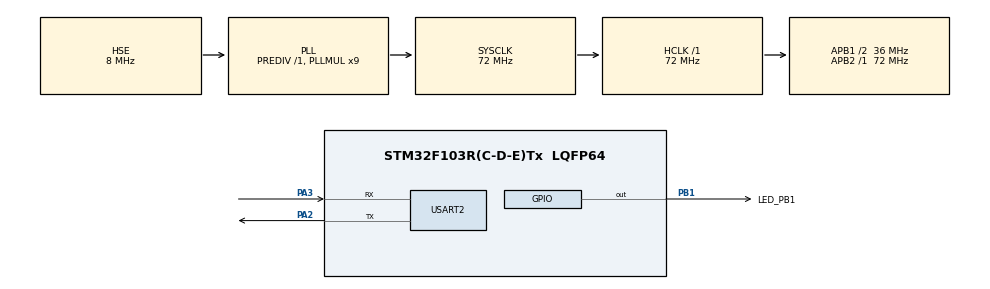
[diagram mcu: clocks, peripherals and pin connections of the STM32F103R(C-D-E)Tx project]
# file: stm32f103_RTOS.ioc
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FREERTOS.Tasks01=defaultTask,0,128,StartDefaultTask,Default,NULL
Mcu.Family=STM32F1
Mcu.Name=STM32F103R(C-D-E)Tx
Mcu.Package=LQFP64
NVIC.PriorityGroup=NVIC_PRIORITYGROUP_4
NVIC.TIM7_IRQn=true\:0\:0\:false\:false\:true\:false\:false\:true
NVIC.TimeBase=TIM7_IRQn
NVIC.TimeBaseIP=TIM7
NVIC.USART2_IRQn=true\:5\:0\:false\:false\:true\:true\:true\:true
PA13.Mode=Trace_Asynchronous_SW
PA13.Signal=SYS_JTMS-SWDIO
PA14.Mode=Trace_Asynchronous_SW
PA14.Signal=SYS_JTCK-SWCLK
PA2.Mode=Asynchronous
PA2.Signal=USART2_TX
PA3.Mode=Asynchronous
PA3.Signal=USART2_RX
PB1.GPIO_Label=LED_PB1
PB1.PinState=GPIO_PIN_SET
PB1.Signal=GPIO_Output
PB3.Mode=Trace_Asynchronous_SW
PB3.Signal=SYS_JTDO-TRACESWO
PD0-OSC_IN.Mode=HSE-External-Oscillator
PD0-OSC_IN.Signal=RCC_OSC_IN
PD1-OSC_OUT.Mode=HSE-External-Oscillator
PD1-OSC_OUT.Signal=RCC_OSC_OUT
ProjectManager.HeapSize=0x200
ProjectManager.StackSize=0x400
ProjectManager.TargetToolchain=TrueSTUDIO
RCC.AHBFreq_Value=72000000
RCC.APB1CLKDivider=RCC_HCLK_DIV2
RCC.APB1Freq_Value=36000000
RCC.APB1TimFreq_Value=72000000
RCC.APB2Freq_Value=72000000
RCC.APB2TimFreq_Value=72000000
RCC.HCLKFreq_Value=72000000
RCC.PLLMUL=RCC_PLL_MUL9
RCC.PLLSourceVirtual=RCC_PLLSOURCE_HSE
RCC.SYSCLKFreq_VALUE=72000000
RCC.SYSCLKSource=RCC_SYSCLKSOURCE_PLLCLK
RCC.USBFreq_Value=72000000
USART2.VirtualMode=VM_ASYNC
VP_FREERTOS_VS_CMSIS_V1.Mode=CMSIS_V1
VP_SYS_VS_tim7.Mode=TIM7
board=custom

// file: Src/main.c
/* USER CODE BEGIN Header */
/**
  ******************************************************************************
  * @file           : main.c
  * @brief          : Main program body
  ******************************************************************************
  * @attention
  *
  * <h2><center>&copy; Copyright (c) 2019 STMicroelectronics.
  * All rights reserved.</center></h2>
  *
  * This software component is licensed by ST under Ultimate Liberty license
  * SLA0044, the "License"; You may not use this file except in compliance with
  * the License. You may obtain a copy of the License at:
  *                             www.st.com/SLA0044
  *
  ******************************************************************************
  */
/* USER CODE END Header */

#include "main.h"
#include "cmsis_os.h"
#include "usart.h"
#include "gpio.h"

/* USER CODE BEGIN PTD */
#ifdef __GNUC__
/* With GCC, small printf (option LD Linker->Libraries->Small printf
   set to 'Yes') calls __io_putchar() */
#define PUTCHAR_PROTOTYPE int __io_putchar(int ch)
#else
#define PUTCHAR_PROTOTYPE int fputc(int ch, FILE *f)
#endif /* __GNUC__ */

/* USER CODE END PTD */

void SystemClock_Config(void);
void MX_FREERTOS_Init(void);

int main(void)
{

  /* MCU Configuration--------------------------------------------------------*/

  /* Reset of all peripherals, Initializes the Flash interface and the Systick. */
  HAL_Init();

  /* Configure the system clock */
  SystemClock_Config();

  /* Initialize all configured peripherals */
  MX_GPIO_Init();
  MX_USART2_UART_Init();

  /* Call init function for freertos objects (in freertos.c) */
  MX_FREERTOS_Init();

  /* Start scheduler */
  osKernelStart();

  /* We should never get here as control is now taken by the scheduler */

  /* Infinite loop */
  /* USER CODE BEGIN WHILE */
  //printf("Test RTOS\r\n");

  while (1)
  {
    /* USER CODE END WHILE */
	  //printf("Test while\r\n");

  }
}

void SystemClock_Config(void)
{
  RCC_OscInitTypeDef RCC_OscInitStruct = {0};
  RCC_ClkInitTypeDef RCC_ClkInitStruct = {0};

  /** Initializes the CPU, AHB and APB busses clocks
  */
  RCC_OscInitStruct.OscillatorType = RCC_OSCILLATORTYPE_HSE;
  RCC_OscInitStruct.HSEState = RCC_HSE_ON;
  RCC_OscInitStruct.HSEPredivValue = RCC_HSE_PREDIV_DIV1;
  RCC_OscInitStruct.HSIState = RCC_HSI_ON;
  RCC_OscInitStruct.PLL.PLLState = RCC_PLL_ON;
  RCC_OscInitStruct.PLL.PLLSource = RCC_PLLSOURCE_HSE;
  RCC_OscInitStruct.PLL.PLLMUL = RCC_PLL_MUL9;
  if (HAL_RCC_OscConfig(&RCC_OscInitStruct) != HAL_OK)
  {
    Error_Handler();
  }
  /** Initializes the CPU, AHB and APB busses clocks
  */
  RCC_ClkInitStruct.ClockType = RCC_CLOCKTYPE_HCLK|RCC_CLOCKTYPE_SYSCLK
                              |RCC_CLOCKTYPE_PCLK1|RCC_CLOCKTYPE_PCLK2;
  RCC_ClkInitStruct.SYSCLKSource = RCC_SYSCLKSOURCE_PLLCLK;
  RCC_ClkInitStruct.AHBCLKDivider = RCC_SYSCLK_DIV1;
  RCC_ClkInitStruct.APB1CLKDivider = RCC_HCLK_DIV2;
  RCC_ClkInitStruct.APB2CLKDivider = RCC_HCLK_DIV1;

  if (HAL_RCC_ClockConfig(&RCC_ClkInitStruct, FLASH_LATENCY_2) != HAL_OK)
  {
    Error_Handler();
  }
}

/* USER CODE BEGIN 4 */

PUTCHAR_PROTOTYPE
{
  /* Place your implementation of fputc here */
  /* e.g. write a character to the USART2 and Loop until the end of transmission */
  HAL_UART_Transmit(&huart2, (uint8_t *)&ch, 1, 0xFFFF);

  return ch;
}

/* USER CODE END 4 */

void HAL_TIM_PeriodElapsedCallback(TIM_HandleTypeDef *htim)
{
  if (htim->Instance == TIM7) {
    HAL_IncTick();
  }
}

void Error_Handler(void)
{
}

/************************ (C) COPYRIGHT STMicroelectronics *****END OF FILE****/

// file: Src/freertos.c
/* USER CODE BEGIN Header */
/**
  ******************************************************************************
  * File Name          : freertos.c
  * Description        : Code for freertos applications
  ******************************************************************************
  * @attention
  *
  * <h2><center>&copy; Copyright (c) 2019 STMicroelectronics.
  * All rights reserved.</center></h2>
  *
  * This software component is licensed by ST under Ultimate Liberty license
  * SLA0044, the "License"; You may not use this file except in compliance with
  * the License. You may obtain a copy of the License at:
  *                             www.st.com/SLA0044
  *
  ******************************************************************************
  */
/* USER CODE END Header */

#include "FreeRTOS.h"
#include "task.h"
#include "main.h"
#include "cmsis_os.h"

osThreadId defaultTaskHandle;

void StartDefaultTask(void const * argument);
void StartDefaultTask1(void const * argument);
void StartDefaultTask2(void const * argument);

void MX_FREERTOS_Init(void); /* (MISRA C 2004 rule 8.1) */

void MX_FREERTOS_Init(void) {

  /* Create the thread(s) */
  /* definition and creation of defaultTask */
  osThreadDef(defaultTask, StartDefaultTask, osPriorityNormal, 0, 128);
  defaultTaskHandle = osThreadCreate(osThread(defaultTask), NULL);

  /* USER CODE BEGIN RTOS_THREADS */
  /* add threads, ... */
  //printf("Start: \r\n");
  osThreadDef(defaultTask2, StartDefaultTask2, osPriorityNormal, 0, 128);
    defaultTaskHandle = osThreadCreate(osThread(defaultTask2), NULL);

    //osThreadDef(defaultTask1, StartDefaultTask1, osPriorityNormal, 0, 128);
        //defaultTaskHandle = osThreadCreate(osThread(defaultTask1), NULL);
  /* USER CODE END RTOS_THREADS */

}

void StartDefaultTask(void const * argument)
{

  /* USER CODE BEGIN StartDefaultTask */
  /* Infinite loop */
  for(;;)
  {
	  printf("\r\nWhat?\r\n");
    osDelay(5);
  }
  /* USER CODE END StartDefaultTask */
}

/* USER CODE BEGIN Application */
void StartDefaultTask1(void const * argument)
{

  /* USER CODE BEGIN StartDefaultTask */
  /* Infinite loop */
  for(;;)
  {
	  printf("\r\n Hello RTOS 1!\r\n");
    osDelay(1);
  }
  /* USER CODE END StartDefaultTask */
}

void StartDefaultTask2(void const * argument)
{

  /* USER CODE BEGIN StartDefaultTask */
  /* Infinite loop */
  for(;;)
  {
	  printf("\r\n Hello RTOS 2!\r\n");
    osDelay(1);
  }
  /* USER CODE END StartDefaultTask */
}

/* USER CODE END Application */

/************************ (C) COPYRIGHT STMicroelectronics *****END OF FILE****/
